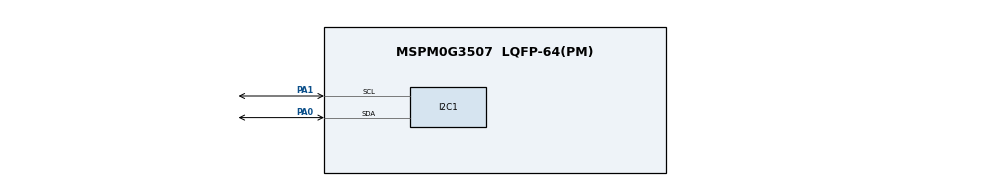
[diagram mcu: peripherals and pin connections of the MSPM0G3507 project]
// @cliArgs --device "MSPM0G350X" --package "LQFP-64(PM)" --part "Default" 
// @v2CliArgs --device "MSPM0G3507" --package "LQFP-64(PM)" 
// @cliArgs --board /ti/boards/LP_MSPM0G3507 --rtos nortos

/**
 * Import the modules used in this configuration.
 */
const Board = scripting.addModule("/ti/driverlib/Board");
const CRC   = scripting.addModule("/ti/driverlib/CRC");
const I2C   = scripting.addModule("/ti/driverlib/I2C", {}, false);
const I2C1  = I2C.addInstance();

/**
 * Write custom configuration values to the imported modules.
 */

CRC.polynomial = "16_POLYNOMIAL";
CRC.seed       = 0xFFFF;

I2C1.basicEnableController             = true;
I2C1.advControllerTXFIFOTRIG           = "BYTES_1";
I2C1.$name                             = "I2C";
I2C1.advAnalogGlitchFilter             = "DISABLED";
I2C1.intController                     = ["ARBITRATION_LOST","NACK","RXFIFO_TRIGGER","RX_DONE","TX_DONE"];
I2C1.peripheral.$assign                = "I2C0";
I2C1.peripheral.sdaPin.$assign         = "PA0";
I2C1.peripheral.sclPin.$assign         = "PA1";
I2C1.sdaPinConfig.enableConfig         = true;
I2C1.sclPinConfig.enableConfig         = true;

const SYSCTL                 = scripting.addModule("/ti/driverlib/SYSCTL", {}, false);
SYSCTL.forceDefaultClkConfig = true;
SYSCTL.clockTreeEn           = true;
